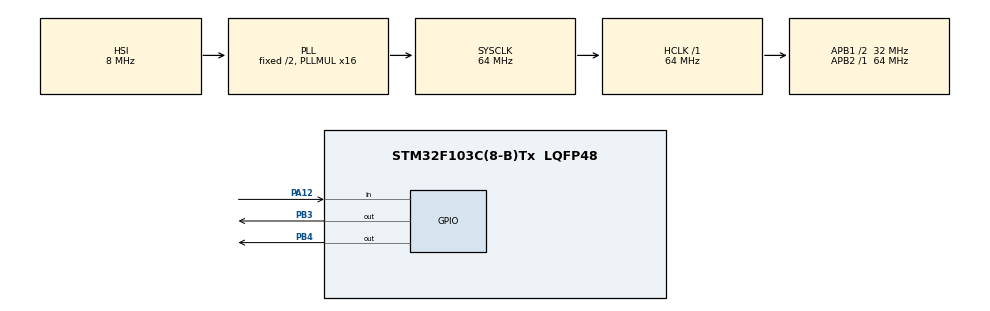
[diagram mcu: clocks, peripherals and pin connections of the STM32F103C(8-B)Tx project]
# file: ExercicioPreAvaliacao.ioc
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FREERTOS.Tasks01=defaultTask,8,128,StartDefaultTask,Default,NULL,Dynamic,NULL,NULL;myTask02,40,128,StartTask02,Default,NULL,Dynamic,NULL,NULL;myTask03,24,128,StartTask03,Default,NULL,Dynamic,NULL,NULL
Mcu.Family=STM32F1
Mcu.Name=STM32F103C(8-B)Tx
Mcu.Package=LQFP48
NVIC.PriorityGroup=NVIC_PRIORITYGROUP_4
PA12.GPIO_PuPd=GPIO_PULLUP
PA12.Signal=GPIO_Input
PA13.Mode=Serial_Wire
PA13.Signal=SYS_JTMS-SWDIO
PA14.Mode=Serial_Wire
PA14.Signal=SYS_JTCK-SWCLK
PB3.Signal=GPIO_Output
PB4.Signal=GPIO_Output
ProjectManager.HeapSize=0x200
ProjectManager.StackSize=0x400
ProjectManager.TargetToolchain=STM32CubeIDE
RCC.AHBFreq_Value=64000000
RCC.APB1CLKDivider=RCC_HCLK_DIV2
RCC.APB1Freq_Value=32000000
RCC.APB1TimFreq_Value=64000000
RCC.APB2Freq_Value=64000000
RCC.APB2TimFreq_Value=64000000
RCC.HCLKFreq_Value=64000000
RCC.PLLMUL=RCC_PLL_MUL16
RCC.SYSCLKFreq_VALUE=64000000
RCC.SYSCLKSource=RCC_SYSCLKSOURCE_PLLCLK
RCC.USBFreq_Value=64000000
VP_FREERTOS_VS_CMSIS_V2.Mode=CMSIS_V2
board=custom

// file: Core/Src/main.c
/* USER CODE BEGIN Header */
/**
  ******************************************************************************
  * @file           : main.c
  * @brief          : Main program body
  ******************************************************************************
  * @attention
  *
  * <h2><center>&copy; Copyright (c) 2025 STMicroelectronics.
  * All rights reserved.</center></h2>
  *
  * This software component is licensed by ST under BSD 3-Clause license,
  * the "License"; You may not use this file except in compliance with the
  * License. You may obtain a copy of the License at:
  *                        opensource.org/licenses/BSD-3-Clause
  *
  ******************************************************************************
  */
/* USER CODE END Header */
#include "main.h"
#include "cmsis_os.h"

/* USER CODE BEGIN PD */
#define ON_5 HAL_GPIO_WritePin(GPIOB, GPIO_PIN_5, 1)
#define OFF_5 HAL_GPIO_WritePin(GPIOB, GPIO_PIN_5, 0)
#define ON_4 HAL_GPIO_WritePin(GPIOB, GPIO_PIN_4, 1)
#define OFF_4 HAL_GPIO_WritePin(GPIOB, GPIO_PIN_4, 0)
/* USER CODE END PD */

/* Definitions for defaultTask */
osThreadId_t defaultTaskHandle;
const osThreadAttr_t defaultTask_attributes = {
  .name = "defaultTask",
  .priority = (osPriority_t) osPriorityLow,
  .stack_size = 128 * 4
};
/* Definitions for myTask02 */
osThreadId_t myTask02Handle;
const osThreadAttr_t myTask02_attributes = {
  .name = "myTask02",
  .priority = (osPriority_t) osPriorityHigh,
  .stack_size = 128 * 4
};
/* Definitions for myTask03 */
osThreadId_t myTask03Handle;
const osThreadAttr_t myTask03_attributes = {
  .name = "myTask03",
  .priority = (osPriority_t) osPriorityNormal,
  .stack_size = 128 * 4
};
/* USER CODE BEGIN PV */
 uint8_t volatile cont = 0;
/* USER CODE END PV */

void SystemClock_Config(void);
static void MX_GPIO_Init(void);
void StartDefaultTask(void *argument);
void StartTask02(void *argument);
void StartTask03(void *argument);

int main(void)
{

  /* MCU Configuration--------------------------------------------------------*/

  /* Reset of all peripherals, Initializes the Flash interface and the Systick. */
  HAL_Init();

  /* Configure the system clock */
  SystemClock_Config();

  /* Initialize all configured peripherals */
  MX_GPIO_Init();

  /* Init scheduler */
  osKernelInitialize();

  /* Create the thread(s) */
  /* creation of defaultTask */
  defaultTaskHandle = osThreadNew(StartDefaultTask, NULL, &defaultTask_attributes);

  /* creation of myTask02 */
  myTask02Handle = osThreadNew(StartTask02, NULL, &myTask02_attributes);

  /* creation of myTask03 */
  myTask03Handle = osThreadNew(StartTask03, NULL, &myTask03_attributes);

  /* Start scheduler */
  osKernelStart();

  /* We should never get here as control is now taken by the scheduler */
  /* Infinite loop */
  while (1)
  {

  }
}

void SystemClock_Config(void)
{
  RCC_OscInitTypeDef RCC_OscInitStruct = {0};
  RCC_ClkInitTypeDef RCC_ClkInitStruct = {0};

  /** Initializes the RCC Oscillators according to the specified parameters
  * in the RCC_OscInitTypeDef structure.
  */
  RCC_OscInitStruct.OscillatorType = RCC_OSCILLATORTYPE_HSI;
  RCC_OscInitStruct.HSIState = RCC_HSI_ON;
  RCC_OscInitStruct.HSICalibrationValue = RCC_HSICALIBRATION_DEFAULT;
  RCC_OscInitStruct.PLL.PLLState = RCC_PLL_ON;
  RCC_OscInitStruct.PLL.PLLSource = RCC_PLLSOURCE_HSI_DIV2;
  RCC_OscInitStruct.PLL.PLLMUL = RCC_PLL_MUL16;
  if (HAL_RCC_OscConfig(&RCC_OscInitStruct) != HAL_OK)
  {
    Error_Handler();
  }
  /** Initializes the CPU, AHB and APB buses clocks
  */
  RCC_ClkInitStruct.ClockType = RCC_CLOCKTYPE_HCLK|RCC_CLOCKTYPE_SYSCLK
                              |RCC_CLOCKTYPE_PCLK1|RCC_CLOCKTYPE_PCLK2;
  RCC_ClkInitStruct.SYSCLKSource = RCC_SYSCLKSOURCE_PLLCLK;
  RCC_ClkInitStruct.AHBCLKDivider = RCC_SYSCLK_DIV1;
  RCC_ClkInitStruct.APB1CLKDivider = RCC_HCLK_DIV2;
  RCC_ClkInitStruct.APB2CLKDivider = RCC_HCLK_DIV1;

  if (HAL_RCC_ClockConfig(&RCC_ClkInitStruct, FLASH_LATENCY_2) != HAL_OK)
  {
    Error_Handler();
  }
}

static void MX_GPIO_Init(void)
{
  GPIO_InitTypeDef GPIO_InitStruct = {0};

  /* GPIO Ports Clock Enable */
  __HAL_RCC_GPIOA_CLK_ENABLE();
  __HAL_RCC_GPIOB_CLK_ENABLE();

  /*Configure GPIO pin Output Level */
  HAL_GPIO_WritePin(GPIOB, GPIO_PIN_3|GPIO_PIN_4, GPIO_PIN_RESET);

  /*Configure GPIO pin : PA12 */
  GPIO_InitStruct.Pin = GPIO_PIN_12;
  GPIO_InitStruct.Mode = GPIO_MODE_INPUT;
  GPIO_InitStruct.Pull = GPIO_PULLUP;
  HAL_GPIO_Init(GPIOA, &GPIO_InitStruct);

  /*Configure GPIO pins : PB3 PB4 */
  GPIO_InitStruct.Pin = GPIO_PIN_3|GPIO_PIN_4;
  GPIO_InitStruct.Mode = GPIO_MODE_OUTPUT_PP;
  GPIO_InitStruct.Pull = GPIO_NOPULL;
  GPIO_InitStruct.Speed = GPIO_SPEED_FREQ_LOW;
  HAL_GPIO_Init(GPIOB, &GPIO_InitStruct);

}

void StartDefaultTask(void *argument)
{
  /* USER CODE BEGIN 5 */
  /* Infinite loop */
  for(;;)
  {
	ON_3;
	osDelay(100);
	OFF_3;
	osDelay(100);
  }
  /* USER CODE END 5 */
}

void StartTask02(void *argument)
{
  /* USER CODE BEGIN StartTask02 */
	uint8_t botao_anterior = 1;
	uint8_t botao_cont = 0;
	uint8_t botao;
  /* Infinite loop */
  for(;;)
  {
	  botao = HAL_GPIO_ReadPin(GPIOA, GPIO_PIN_12);
	  if (botao == botao_anterior)
	  {
		  if (botao_cont < 10) botao_cont++;
	  }
	  else
	  {
		  botao_cont = 0;
		  botao_anterior = botao;
	  }
	  if (botao_cont == 5 && botao == 0)
	  {
	    cont++;
	    if (cont > 21) cont = 21;
	    botao_cont = 0;
	  }
    osDelay(10);
  }
  /* USER CODE END StartTask02 */
}

void StartTask03(void *argument)
{
  /* USER CODE BEGIN StartTask03 */
  /* Infinite loop */
  for(;;)
  {
	if(cont < 11){
		ON_4;
		osDelay(250);
		OFF_4;
		osDelay(250);
	}
	else if (cont == 11 || cont <= 20){
		ON_4;
		osDelay(100);
		OFF_4;
		osDelay(100);
	}
	else{
		ON_4;
	}
    osDelay(1);
  }
  /* USER CODE END StartTask03 */
}

void Error_Handler(void)
{
  __disable_irq();
  while (1)
  {
  }
}

/************************ (C) COPYRIGHT STMicroelectronics *****END OF FILE****/
